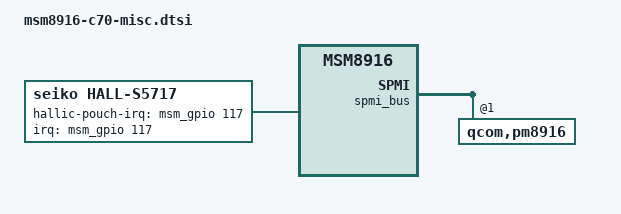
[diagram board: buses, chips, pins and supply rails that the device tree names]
/* Copyright (c) 2012, Code Aurora Forum. All rights reserved.
 *
 * This program is free software; you can redistribute it and/or modify
 * it under the terms of the GNU General Public License version 2 and
 * only version 2 as published by the Free Software Foundation.
 *
 * This program is distributed in the hope that it will be useful,
 * but WITHOUT ANY WARRANTY; without even the implied warranty of
 * MERCHANTABILITY or FITNESS FOR A PARTICULAR PURPOSE.  See the
 * GNU General Public License for more details.
 */

&soc {
	hall-s5717 {
		compatible = "seiko,hall-s5717";
		interrupt-parent = <&msm_gpio>;
		interrupts = <117 0x0>;
		hallic-pouch-irq-gpio = <&msm_gpio 117 0x00>;
		status = "okay";
	};
};

&spmi_bus {
	qcom,pm8916@1 {
		qcom,vibrator@c000 {
			status = "ok";
			qcom,vib-timeout-ms = <15000>;
			qcom,vib-vtg-level-mV = <3100>;
		};
	};
};
/* Merged to msm8916-e2-camera.dtsi (for flash led driver)*/
&i2c_4 {
	lp5521@32 {
		revision = "...rev_a";
		compatible = "ti,lp5521";
		status = "disable";
		reg = <0x32>;
		ti,led_en = <&msm_gpio 120 0x1>;
	};

};
